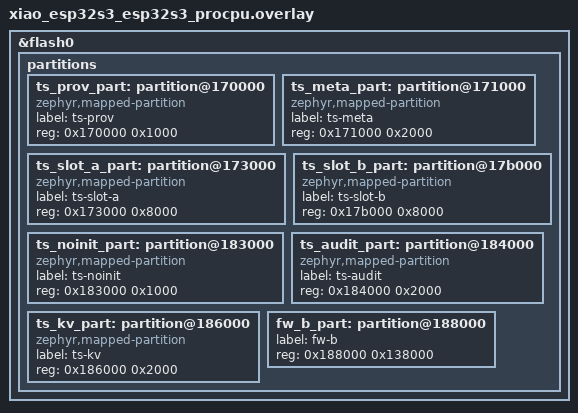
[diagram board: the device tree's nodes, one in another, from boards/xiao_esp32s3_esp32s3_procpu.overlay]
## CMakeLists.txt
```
# SPDX-License-Identifier: Apache-2.0
cmake_minimum_required(VERSION 3.20.0)
find_package(Zephyr REQUIRED HINTS $ENV{ZEPHYR_BASE})
project(tessera_app)

target_sources(app PRIVATE src/main.c)
```

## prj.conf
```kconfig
# SPDX-License-Identifier: Apache-2.0
# M1：ts-core + ts-safety 接入（design/LLD-ts-core / LLD-ts-safety）。
CONFIG_PRINTK=y
CONFIG_TS_CORE=y
CONFIG_TS_SAFETY=y

# DEC-49：生产 app 同样承担安装/验签路径（twister smoke 即此构建）——
# tweetnacl 验签深度要求主栈 ≥8192（net_wq 已在模块内 8192）。
CONFIG_MAIN_STACK_SIZE=8192

# V3-1 flash 面（V2-2 既定待办）：分区 overlay 见 boards/*.overlay；
# store 基座可移植（native_sim = RAM 后端），flash/audit 走板级片段。
CONFIG_TS_STORE=y
```

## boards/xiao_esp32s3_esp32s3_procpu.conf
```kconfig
# xiao_esp32s3 每板预算（板级六起生效；DEC-23/27 + HLD §4.6）
# 板：ESP32-S3 512KB 内部 SRAM + N8R8 模组 8MB 八线 PSRAM。
# 板级六修正：早期"Zephyr 4.4 无 psram 节点、PSRAM 暂不可用"评估有误——
# psram0 节点在 esp32s3_common.dtsi，N8R8 模组 dtsi 定 8MB（octal）。
# WAMR 实例堆入 PSRAM（HLD §4.6 分层纪律：仅 APP 沙箱内存可入外部 RAM，
# 框架安全数据/zenoh/WAMR 运行时控制面留内部 SRAM）。
CONFIG_TS_STORE_SLOT_SIZE=32768
CONFIG_TS_APP_THREAD_STACK=16384
CONFIG_ESP_SPIRAM=y
CONFIG_SPIRAM_MODE_OCT=y
CONFIG_ESP_SPIRAM_MEMTEST=y
CONFIG_TS_APP_PSRAM_HEAP=y
CONFIG_TS_APP_WAMR_HEAP=262144

# V3-1 flash 面：ts 六分区 + 审计持久化（auditbench 同款）
CONFIG_FLASH=y
CONFIG_FLASH_MAP=y
CONFIG_TS_STORE_FLASH=y
CONFIG_TS_STORE_AUDIT=y

# V0.4.0 M9（DR-15）：APP 状态 kv
CONFIG_TS_STORE_KV=y
```

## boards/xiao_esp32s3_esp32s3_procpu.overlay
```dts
/*
 * V3-1（V2-2 既定待办「生产 app flash 面接入」）：auditbench 同款
 * ts 五分区 + ts-audit 8KB（两页乒乓，DEC-52①）；fw-b 预留缩至 0x186000
 * 起（借头部 8KB，esptool 偏移零变化——V1 未接线）。
 */
/delete-node/ &slot1_partition;

&flash0 {
	partitions {
		ts_prov_part: partition@170000 {
			compatible = "zephyr,mapped-partition";
			label = "ts-prov";
			reg = <0x170000 0x1000>;
		};
		ts_meta_part: partition@171000 {
			compatible = "zephyr,mapped-partition";
			label = "ts-meta";
			reg = <0x171000 0x2000>;
		};
		ts_slot_a_part: partition@173000 {
			compatible = "zephyr,mapped-partition";
			label = "ts-slot-a";
			reg = <0x173000 0x8000>;
		};
		ts_slot_b_part: partition@17b000 {
			compatible = "zephyr,mapped-partition";
			label = "ts-slot-b";
			reg = <0x17b000 0x8000>;
		};
		ts_noinit_part: partition@183000 {
			compatible = "zephyr,mapped-partition";
			label = "ts-noinit";
			reg = <0x183000 0x1000>;
		};
		/* DEC-52①：审计 flash 环 8KB（两页 × 4KB × 64 槽 × 64B） */
		ts_audit_part: partition@184000 {
			compatible = "zephyr,mapped-partition";
			label = "ts-audit";
			reg = <0x184000 0x2000>;
		};
		/* V0.4.0 M9（DR-15）：APP 状态 kv 8KB（两页 × 15 槽 × 264B） */
		ts_kv_part: partition@186000 {
			compatible = "zephyr,mapped-partition";
			label = "ts-kv";
			reg = <0x186000 0x2000>;
		};
		/* fw-b：预留缩至 0x188000 起（audit/kv 连续借位） */
		fw_b_part: partition@188000 {
			label = "fw-b";
			reg = <0x188000 0x138000>;
		};
	};
};
```

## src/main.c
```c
/* SPDX-License-Identifier: Apache-2.0 */
/*
 * Tessera firmware application（M1：ts-core + ts-safety 最小闭环）。
 * main 仅启动框架：固定顺序初始化（LLD-ts-core §2）→ 监督空转（LLD-ts-common §4）。
 */
#include <zephyr/kernel.h>
#include <zephyr/sys/printk.h>
#include <ts/core.h>

int main(void)
{
	printk("Tessera firmware (ts-core + ts-safety + ts-store)\n");
	ts_core_boot(); /* noreturn */
	CODE_UNREACHABLE;
}
```
